# STM32F030C6T6 register map
File version: 1.0
Registers are 32-bit, access not given, reset 0x0 unless marked. A register's access mark holds for its fields unless they carry their own. Offsets are from the block's base; [hi:lo] are bit positions; {n}, {i} and the like mark numbered series; 'fields as' and 'values as' point back to an identical list.

## PWR
Base 0x40007000
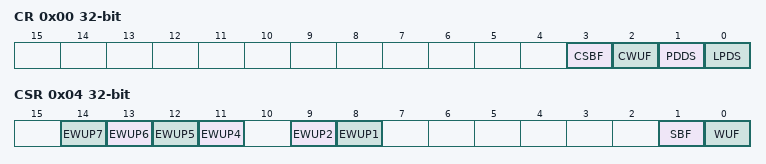
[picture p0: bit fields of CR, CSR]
0x00 CR
  [3] CSBF, [2] CWUF, [1] PDDS, [0] LPDS
0x04 CSR
  [n+7] EWUP{n} (n=4..7), [9] EWUP2, [8] EWUP1, [1] SBF, [0] WUF

## SYSCFG
Base 0x40010000
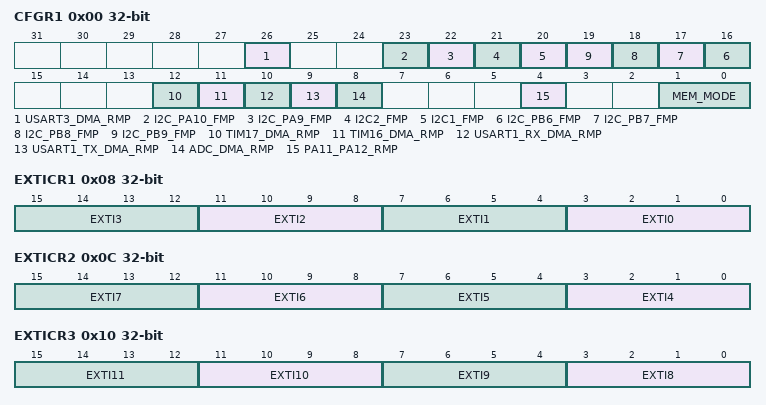
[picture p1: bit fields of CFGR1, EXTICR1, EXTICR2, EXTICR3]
0x00 CFGR1
  [26] USART3_DMA_RMP, [23] I2C_PA10_FMP, [22] I2C_PA9_FMP, [21] I2C2_FMP, [20] I2C1_FMP, [n+10] I2C_PB{n}_FMP (n=6..9), [12] TIM17_DMA_RMP, [11] TIM16_DMA_RMP, [10] USART1_RX_DMA_RMP, [9] USART1_TX_DMA_RMP, [8] ADC_DMA_RMP, [4] PA11_PA12_RMP, [1:0] MEM_MODE
0x08 EXTICR1
  [4n+3:4n] EXTI{n} (n=0..3)
0x0C EXTICR2
  [4n-13:4n-16] EXTI{n} (n=4..7)
0x10 EXTICR3
  [4n-29:4n-32] EXTI{n} (n=8..11)
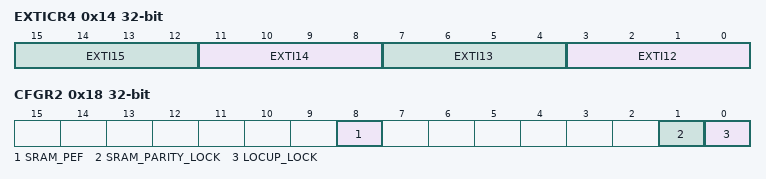
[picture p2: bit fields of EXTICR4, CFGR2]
0x14 EXTICR4
  [4n-45:4n-48] EXTI{n} (n=12..15)
0x18 CFGR2
  [8] SRAM_PEF, [1] SRAM_PARITY_LOCK, [0] LOCUP_LOCK

## EXTI
Base 0x40010400
0x00 IMR
  [31:0] IM
0x04 EMR
  [31:0] EM
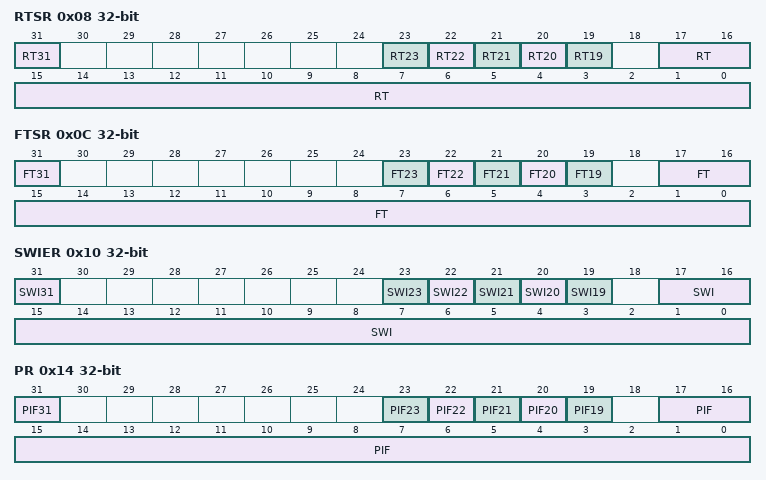
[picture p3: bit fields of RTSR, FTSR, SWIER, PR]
0x08 RTSR
  [31] RT31, [n] RT{n} (n=19..23), [17:0] RT
0x0C FTSR
  [31] FT31, [n] FT{n} (n=19..23), [17:0] FT
0x10 SWIER
  [31] SWI31, [n] SWI{n} (n=19..23), [17:0] SWI
0x14 PR
  [31] PIF31, [n] PIF{n} (n=19..23), [17:0] PIF

## ADC
Base 0x40012400
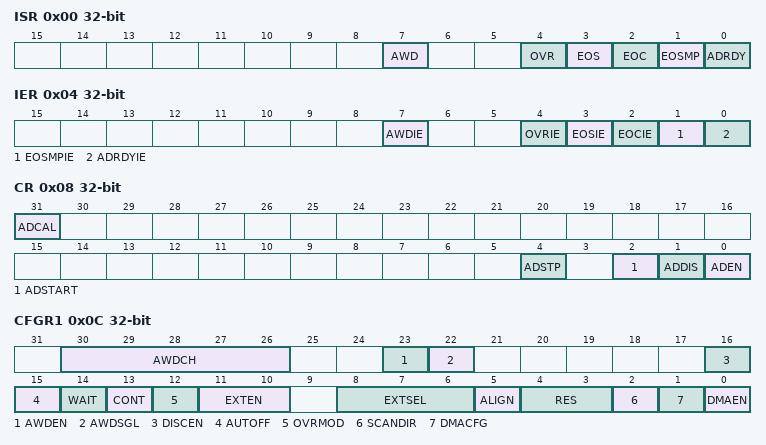
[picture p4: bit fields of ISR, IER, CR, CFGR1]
0x00 ISR
  [7] AWD, [4] OVR, [3] EOS, [2] EOC, [1] EOSMP, [0] ADRDY
0x04 IER
  [7] AWDIE, [4] OVRIE, [3] EOSIE, [2] EOCIE, [1] EOSMPIE, [0] ADRDYIE
0x08 CR
  [31] ADCAL, [4] ADSTP, [2] ADSTART, [1] ADDIS, [0] ADEN
0x0C CFGR1
  [30:26] AWDCH, [23] AWDEN, [22] AWDSGL, [16] DISCEN, [15] AUTOFF, [14] WAIT, [13] CONT, [12] OVRMOD, [11:10] EXTEN, [8:6] EXTSEL, [5] ALIGN, [4:3] RES, [2] SCANDIR, [1] DMACFG, [0] DMAEN
0x10 CFGR2
  [31:30] CKMODE
0x14 SMPR
  [2:0] SMP
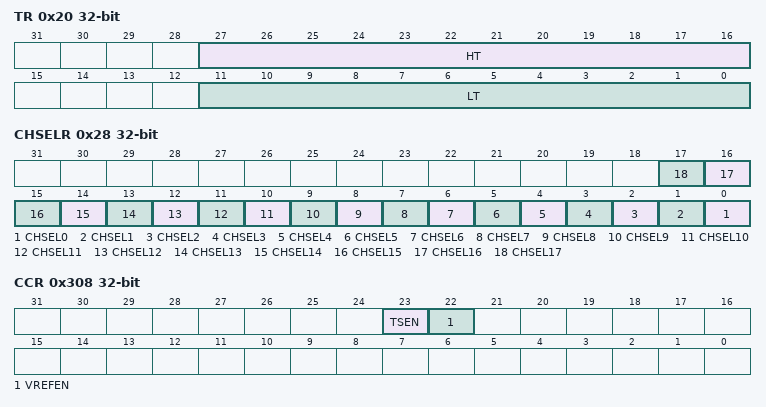
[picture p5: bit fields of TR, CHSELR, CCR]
0x20 TR
  [27:16] HT, [11:0] LT
0x28 CHSELR
  [n] CHSEL{n} (n=0..17)
0x40 DR
  [15:0] DATA
0x308 CCR
  [23] TSEN, [22] VREFEN

## TIM15
Base 0x40014000
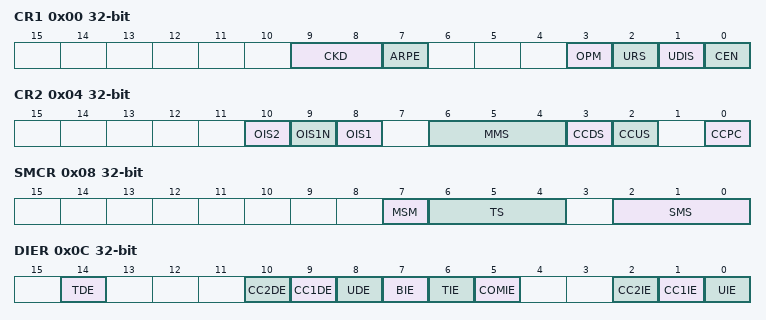
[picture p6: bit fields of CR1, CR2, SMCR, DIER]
0x00 CR1
  [9:8] CKD, [7] ARPE, [3] OPM, [2] URS, [1] UDIS, [0] CEN
0x04 CR2
  [10] OIS2, [9] OIS1N, [8] OIS1, [6:4] MMS, [3] CCDS, [2] CCUS, [0] CCPC
0x08 SMCR
  [7] MSM, [6:4] TS, [2:0] SMS
0x0C DIER
  [14] TDE, [10] CC2DE, [9] CC1DE, [8] UDE, [7] BIE, [6] TIE, [5] COMIE, [2] CC2IE, [1] CC1IE, [0] UIE
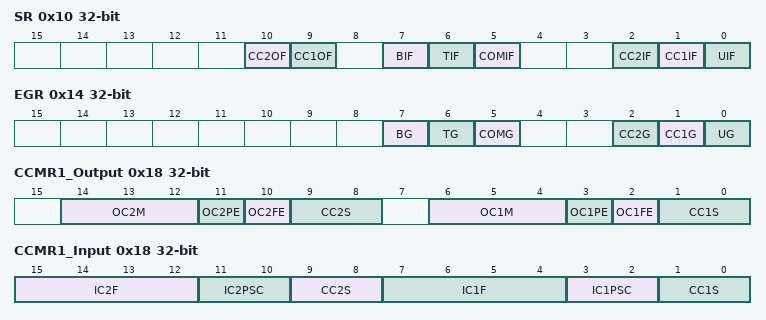
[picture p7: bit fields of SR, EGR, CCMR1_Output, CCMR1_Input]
0x10 SR
  [10] CC2OF, [9] CC1OF, [7] BIF, [6] TIF, [5] COMIF, [2] CC2IF, [1] CC1IF, [0] UIF
0x14 EGR
  [7] BG, [6] TG, [5] COMG, [2] CC2G, [1] CC1G, [0] UG
0x18 CCMR1_Output
  [14:12] OC2M, [11] OC2PE, [10] OC2FE, [9:8] CC2S, [6:4] OC1M, [3] OC1PE, [2] OC1FE, [1:0] CC1S
0x18 CCMR1_Input
  [15:12] IC2F, [11:10] IC2PSC, [9:8] CC2S, [7:4] IC1F, [3:2] IC1PSC, [1:0] CC1S
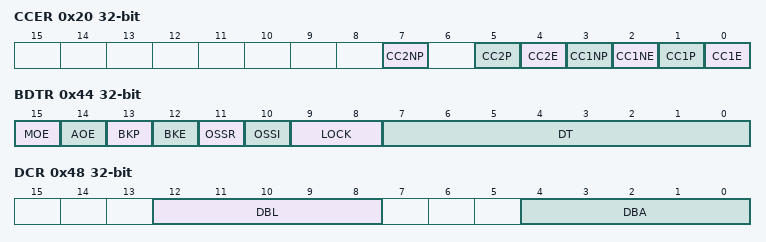
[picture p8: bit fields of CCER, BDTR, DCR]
0x20 CCER
  [7] CC2NP, [5] CC2P, [4] CC2E, [3] CC1NP, [2] CC1NE, [1] CC1P, [0] CC1E
0x24 CNT
  [15:0] CNT
0x28 PSC
  [15:0] PSC
0x2C ARR
  [15:0] ARR
0x30 RCR
  [7:0] REP
0x34 CCR1
  [15:0] CCR1
0x38 CCR2
  [15:0] CCR2
0x44 BDTR
  [15] MOE, [14] AOE, [13] BKP, [12] BKE, [11] OSSR, [10] OSSI, [9:8] LOCK, [7:0] DT
0x48 DCR
  [12:8] DBL, [4:0] DBA
0x4C DMAR
  [15:0] DMAB

## TIM16
Base 0x40014400
Same registers: TIM17 0x40014800
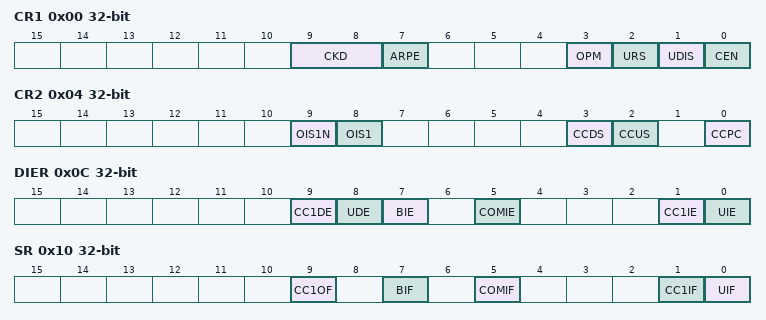
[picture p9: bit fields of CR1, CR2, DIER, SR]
0x00 CR1
  [9:8] CKD, [7] ARPE, [3] OPM, [2] URS, [1] UDIS, [0] CEN
0x04 CR2
  [9] OIS1N, [8] OIS1, [3] CCDS, [2] CCUS, [0] CCPC
0x0C DIER
  [9] CC1DE, [8] UDE, [7] BIE, [5] COMIE, [1] CC1IE, [0] UIE
0x10 SR
  [9] CC1OF, [7] BIF, [5] COMIF, [1] CC1IF, [0] UIF
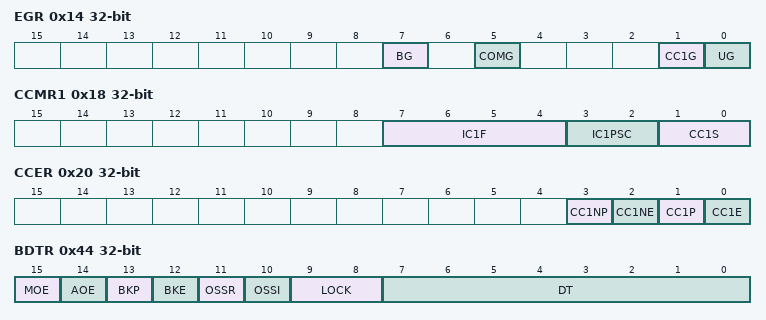
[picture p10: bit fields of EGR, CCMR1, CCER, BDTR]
0x14 EGR
  [7] BG, [5] COMG, [1] CC1G, [0] UG
0x18 CCMR1
  [7:4] IC1F, [3:2] IC1PSC, [1:0] CC1S
0x20 CCER
  [3] CC1NP, [2] CC1NE, [1] CC1P, [0] CC1E
0x24 CNT
  [15:0] CNT
0x28 PSC
  [15:0] PSC
0x2C ARR
  [15:0] ARR
0x30 RCR
  [7:0] REP
0x34 CCR1
  [15:0] CCR1
0x44 BDTR
  [15] MOE, [14] AOE, [13] BKP, [12] BKE, [11] OSSR, [10] OSSI, [9:8] LOCK, [7:0] DT
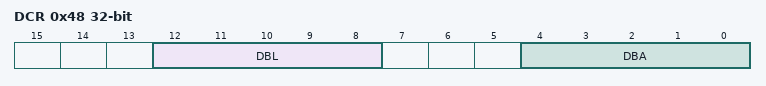
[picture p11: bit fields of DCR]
0x48 DCR
  [12:8] DBL, [4:0] DBA
0x4C DMAR
  [15:0] DMAB

## DMA
Base 0x40020000
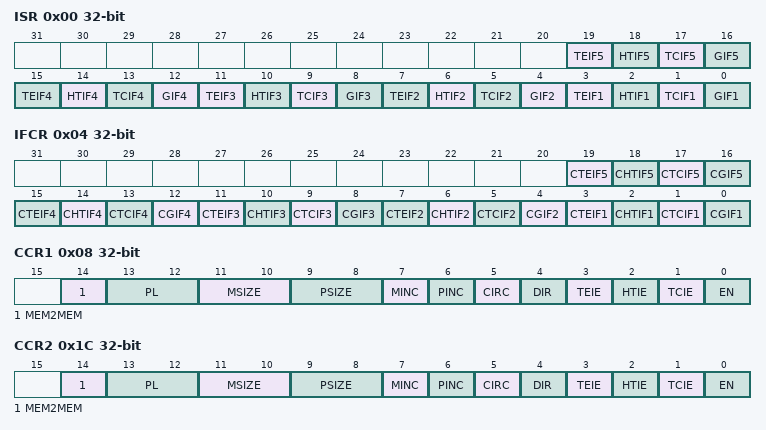
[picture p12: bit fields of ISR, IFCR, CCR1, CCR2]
0x00 ISR
  [4n-1] TEIF{n} (n=1..5), [4n-2] HTIF{n} (n=1..5), [4n-3] TCIF{n} (n=1..5), [4n-4] GIF{n} (n=1..5)
0x04 IFCR
  [4n-1] CTEIF{n} (n=1..5), [4n-2] CHTIF{n} (n=1..5), [4n-3] CTCIF{n} (n=1..5), [4n-4] CGIF{n} (n=1..5)
0x08 CCR1
  [14] MEM2MEM, [13:12] PL, [11:10] MSIZE, [9:8] PSIZE, [7] MINC, [6] PINC, [5] CIRC, [4] DIR, [3] TEIE, [2] HTIE, [1] TCIE, [0] EN
0x0C CNDTR1
  [15:0] NDTR
0x10 CPAR1
  [31:0] PA
{0x0+0x14*i} CMAR{i} (i=1..5)
  [31:0] MA
0x1C CCR2
  fields as CCR1
0x20 CNDTR2
  [15:0] NDTR
0x24 CPAR2
  [31:0] PA
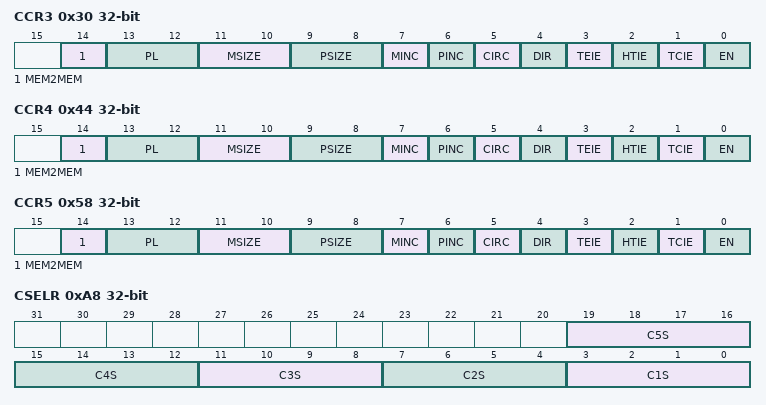
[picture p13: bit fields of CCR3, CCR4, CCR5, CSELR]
0x30 CCR3
  fields as CCR1
0x34 CNDTR3
  [15:0] NDTR
0x38 CPAR3
  [31:0] PA
0x44 CCR4
  fields as CCR1
0x48 CNDTR4
  [15:0] NDTR
0x4C CPAR4
  [31:0] PA
0x58 CCR5
  fields as CCR1
0x5C CNDTR5
  [15:0] NDTR
0x60 CPAR5
  [31:0] PA
0xA8 CSELR
  [4n-1:4n-4] C{n}S (n=1..5)

## RCC
Base 0x40021000
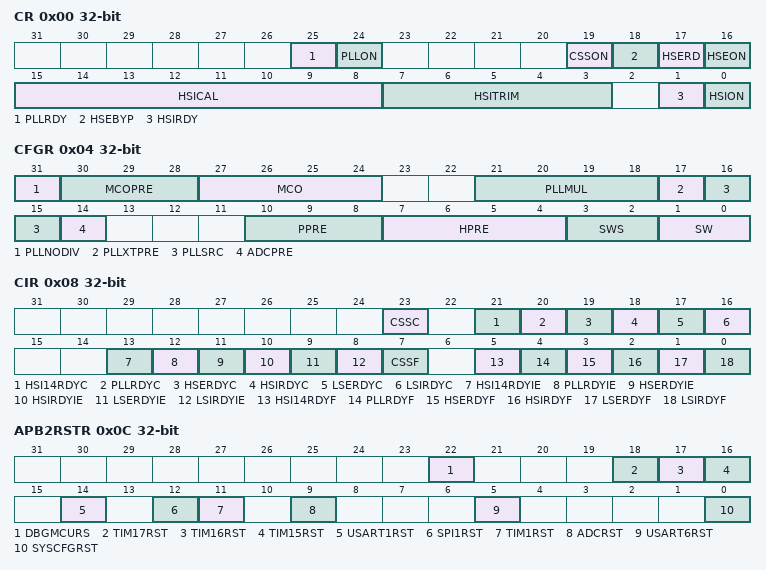
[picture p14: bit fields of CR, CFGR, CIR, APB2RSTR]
0x00 CR
  [25] PLLRDY, [24] PLLON, [19] CSSON, [18] HSEBYP, [17] HSERD, [16] HSEON, [15:8] HSICAL, [7:3] HSITRIM, [1] HSIRDY, [0] HSION
0x04 CFGR
  [31] PLLNODIV, [30:28] MCOPRE, [27:24] MCO, [21:18] PLLMUL, [17] PLLXTPRE, [16:15] PLLSRC, [14] ADCPRE, [10:8] PPRE, [7:4] HPRE, [3:2] SWS, [1:0] SW
0x08 CIR
  [23] CSSC, [21] HSI14RDYC, [20] PLLRDYC, [19] HSERDYC, [18] HSIRDYC, [17] LSERDYC, [16] LSIRDYC, [13] HSI14RDYIE, [12] PLLRDYIE, [11] HSERDYIE, [10] HSIRDYIE, [9] LSERDYIE, [8] LSIRDYIE, [7] CSSF, [5] HSI14RDYF, [4] PLLRDYF, [3] HSERDYF, [2] HSIRDYF, [1] LSERDYF, [0] LSIRDYF
0x0C APB2RSTR
  [22] DBGMCURS, [18] TIM17RST, [17] TIM16RST, [16] TIM15RST, [14] USART1RST, [12] SPI1RST, [11] TIM1RST, [9] ADCRST, [5] USART6RST, [0] SYSCFGRST
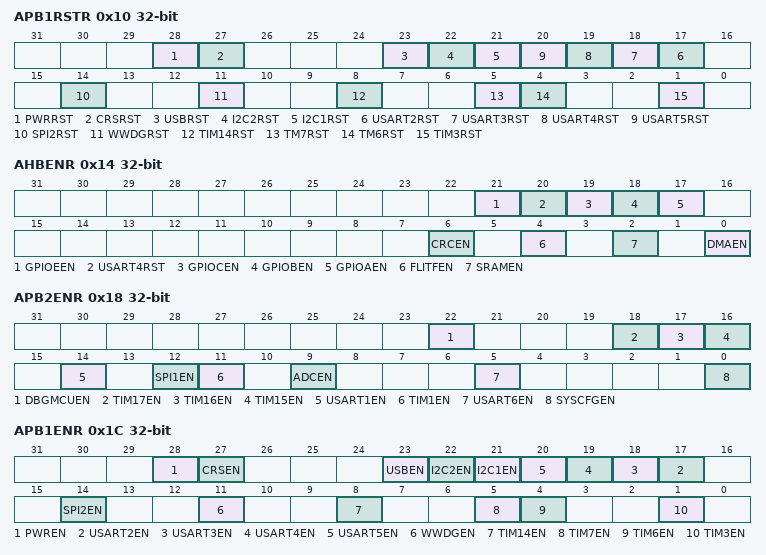
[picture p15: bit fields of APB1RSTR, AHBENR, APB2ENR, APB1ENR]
0x10 APB1RSTR
  [28] PWRRST, [27] CRSRST, [23] USBRST, [22] I2C2RST, [21] I2C1RST, [n+15] USART{n}RST (n=2..5), [14] SPI2RST, [11] WWDGRST, [8] TIM14RST, [5] TM7RST, [4] TM6RST, [1] TIM3RST
0x14 AHBENR
  [21] GPIOEEN, [20] USART4RST, [19] GPIOCEN, [18] GPIOBEN, [17] GPIOAEN, [6] CRCEN, [4] FLITFEN, [2] SRAMEN, [0] DMAEN
0x18 APB2ENR
  [22] DBGMCUEN, [18] TIM17EN, [17] TIM16EN, [16] TIM15EN, [14] USART1EN, [12] SPI1EN, [11] TIM1EN, [9] ADCEN, [5] USART6EN, [0] SYSCFGEN
0x1C APB1ENR
  [28] PWREN, [27] CRSEN, [23] USBEN, [22] I2C2EN, [21] I2C1EN, [n+15] USART{n}EN (n=2..5), [14] SPI2EN, [11] WWDGEN, [8] TIM14EN, [5] TIM7EN, [4] TIM6EN, [1] TIM3EN
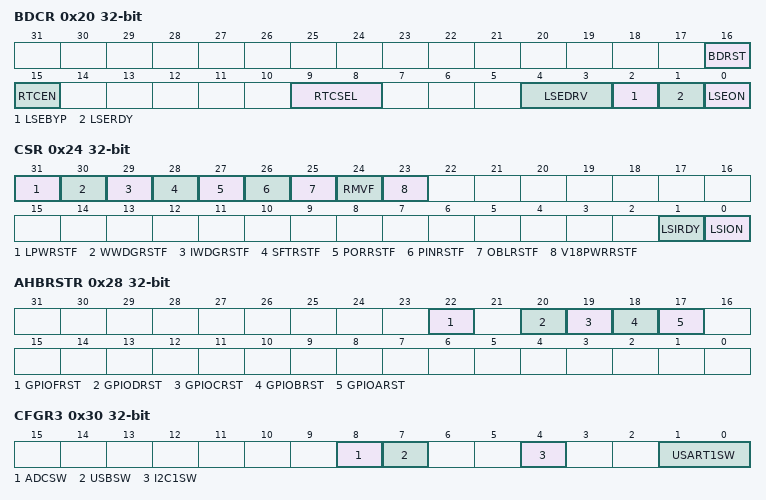
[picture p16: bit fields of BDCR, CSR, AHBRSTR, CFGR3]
0x20 BDCR
  [16] BDRST, [15] RTCEN, [9:8] RTCSEL, [4:3] LSEDRV, [2] LSEBYP, [1] LSERDY, [0] LSEON
0x24 CSR
  [31] LPWRSTF, [30] WWDGRSTF, [29] IWDGRSTF, [28] SFTRSTF, [27] PORRSTF, [26] PINRSTF, [25] OBLRSTF, [24] RMVF, [23] V18PWRRSTF, [1] LSIRDY, [0] LSION
0x28 AHBRSTR
  [22] GPIOFRST, [20] GPIODRST, [19] GPIOCRST, [18] GPIOBRST, [17] GPIOARST
0x2C CFGR2
  [3:0] PREDIV
0x30 CFGR3
  [8] ADCSW, [7] USBSW, [4] I2C1SW, [1:0] USART1SW
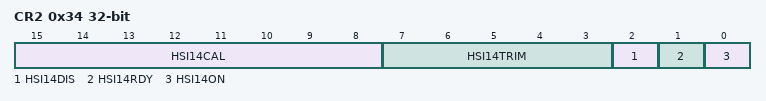
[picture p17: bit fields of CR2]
0x34 CR2
  [15:8] HSI14CAL, [7:3] HSI14TRIM, [2] HSI14DIS, [1] HSI14RDY, [0] HSI14ON

## FLASH
Base 0x40022000
0x00 ACR
  [5] PRFTBS, [4] PRFTBE, [3] HLFCYA, [2:0] LATENCY
0x04 KEYR
  [31:0] FKEY
0x08 OPTKEYR
  [31:0] OPTKEY
0x0C SR
  [5] EOP, [4] WRPRTERR, [2] PGERR, [1] ERLYBSY, [0] BSY
0x10 CR
  [13] OBL_LAUNCH, [12] EOPIE, [10] ERRIE, [9] OPTWRE, [7] LOCK, [6] STRT, [5] OPTER, [4] OPTPG, [2] MER, [1] PER, [0] PG
0x14 AR
  [31:0] FAR
0x1C OBR
  [31:24] Data1, [23:16] Data0, [14] RAM_PARITY_CHECK, [13] VDDA_MONITOR, [12] nBOOT1, [10] nRST_STDBY, [9] nRST_STOP, [8] WDG_SW, [2:1] RDPRT, [0] OPTERR
0x20 WRPR
  [31:0] WRP

## CRC
Base 0x40023000
0x00 DR
0x04 IDR
  [7:0] IDR
0x08 CR
  [7] REV_OUT, [6:5] REV_IN, [0] RESET
0x10 INIT
  [31:0] CRC_INIT

## GPIOA
Base 0x48000000
Same registers: GPIOB 0x48000400, GPIOC 0x48000800, GPIOD 0x48000C00, GPIOF 0x48001400
0x00 MODER
  [2n+1:2n] MODER{n} (n=0..15)
0x04 OTYPER
  [n] OT{n} (n=0..15)
0x08 OSPEEDR
  [2n+1:2n] OSPEEDR{n} (n=0..15)
0x0C PUPDR
  [2n+1:2n] PUPDR{n} (n=0..15)
0x10 IDR
  [n] IDR{n} (n=0..15)
0x14 ODR
  [n] ODR{n} (n=0..15)
0x18 BSRR
  [n+16] BR{n} (n=0..15), [n] BS{n} (n=0..15)
0x1C LCKR
  [16] LCKK, [n] LCK{n} (n=0..15)
0x20 AFRL
  [4n+3:4n] AFSEL{n} (n=0..7)
0x24 AFRH
  [4n-29:4n-32] AFSEL{n} (n=8..15)
0x28 BRR
  [n] BR{n} (n=0..15)
